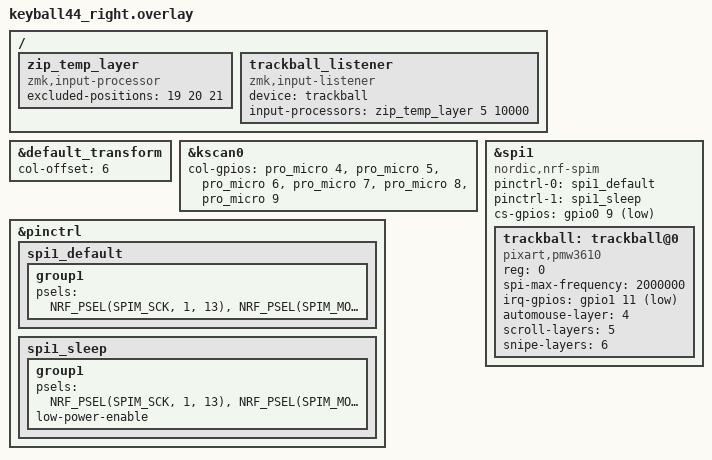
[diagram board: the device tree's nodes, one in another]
/*
 * keyball44_right.overlay
 * 元の overlay にオートマウス停止機能を追加
 */

#include "keyball44.dtsi"

/* --- 既存ノード --- */
&default_transform {
    col-offset = <6>;
};

&kscan0 {
    col-gpios = <
        &pro_micro 4 GPIO_ACTIVE_HIGH,
        &pro_micro 5 GPIO_ACTIVE_HIGH,
        &pro_micro 6 GPIO_ACTIVE_HIGH,
        &pro_micro 7 GPIO_ACTIVE_HIGH,
        &pro_micro 8 GPIO_ACTIVE_HIGH,
        &pro_micro 9 GPIO_ACTIVE_HIGH
    >;
};

&pinctrl {
    spi1_default: spi1_default {
        group1 {
            psels = <
                NRF_PSEL(SPIM_SCK, 1, 13),
                NRF_PSEL(SPIM_MOSI, 0, 10),
                NRF_PSEL(SPIM_MISO, 0, 10)
            >;
        };
    };

    spi1_sleep: spi1_sleep {
        group1 {
            psels = <
                NRF_PSEL(SPIM_SCK, 1, 13),
                NRF_PSEL(SPIM_MOSI, 0, 10),
                NRF_PSEL(SPIM_MISO, 0, 10)
            >;
            low-power-enable;
        };
    };
};

&spi1 {
    status = "okay";
    compatible = "nordic,nrf-spim";
    pinctrl-0 = <&spi1_default>;
    pinctrl-1 = <&spi1_sleep>;
    pinctrl-names = "default", "sleep";
    cs-gpios = <&gpio0 9 GPIO_ACTIVE_LOW>;

    trackball: trackball@0 {
        status = "okay";
        compatible = "pixart,pmw3610";
        reg = <0>;
        spi-max-frequency = <2000000>;
        irq-gpios = <&gpio1 11 (GPIO_ACTIVE_LOW | GPIO_PULL_UP)>;
        automouse-layer = <4>;
        scroll-layers = <5>;
        snipe-layers = <6>;
    };
};

/* --- ここから追加 --- */
 
/ {
    /* J/K/L以外でオートマウスレイヤーを停止する input-processor */
    zip_temp_layer: zip_temp_layer {
        compatible = "zmk,input-processor";
        excluded-positions = <19 20 21>; /* J=19, K=20, L=21 */
    };

    /* trackball イベント用 listener */
    trackball_listener: trackball_listener {
        compatible = "zmk,input-listener";
        device = <&trackball>;
        input-processors = <&zip_temp_layer 5 10000>; /* 5ms, 10000ms (10秒) */
    };
};
